# gcfr_ai87 register map
Registers are read-write, no defined reset value unless marked. A register's access mark holds for its fields unless they carry their own. Offsets are from the block's base; lines under a group give offsets from that group; [hi:lo] are bit positions; {n}, {i} and the like mark numbered series; 'fields as' and 'values as' point back to an identical list; <NAME> marks a mode.

## Memory map
0x40005800 GCFR size 0x400 — Global Control Function Register.

## GCFR — Global Control Function Register.
Base 0x40005800
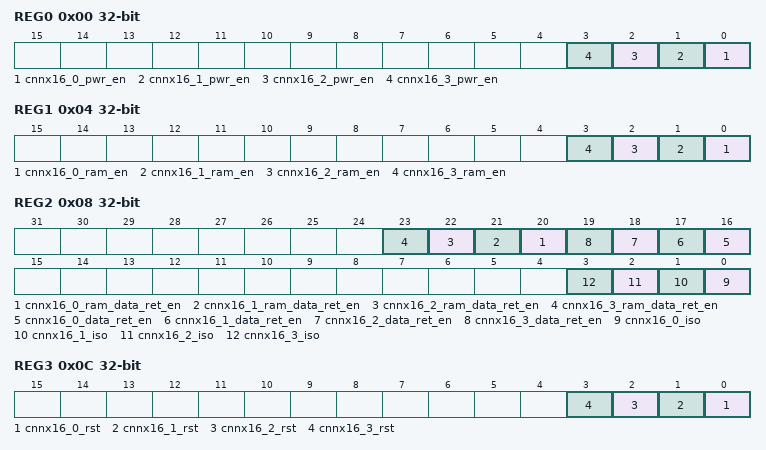
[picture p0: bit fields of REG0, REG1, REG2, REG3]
0x00 REG0 — Register 0.
  [n] cnnx16_{n}_pwr_en (n=0..3) — CNNx16_{n} Power Domain Enable
0x04 REG1 — Register 1.
  [n] cnnx16_{n}_ram_en (n=0..3) — CNNx16_{n} RAM Power Enable
0x08 REG2 — Register 2.
  [n+20] cnnx16_{n}_ram_data_ret_en (n=0..3) — CNNx16_{n} RAM Pad Retention Control
  [n+16] cnnx16_{n}_data_ret_en (n=0..3) — CNNx16_{n} Pad Retention Control
  [n] cnnx16_{n}_iso (n=0..3) — CNNx16_{n} Power Domain Isolation
0x0C REG3 — Register 3.
  [n] cnnx16_{n}_rst (n=0..3) — CNNx16_{n} Power Domain Reset
